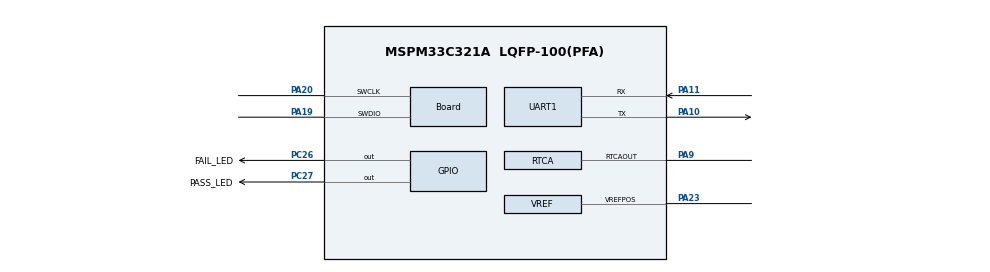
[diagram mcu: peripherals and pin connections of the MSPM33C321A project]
//@cliArgs --device "MSPM33C321A" --package "LQFP-100(PFA)" --part "Default"
//@v2CliArgs --device "MSPM33C321A" --package "LQFP-100(PFA)"
// @cliArgs --board /ti/boards/LP_MSPM33C321A --rtos nortos


/**
 * Import the modules used in this configuration.
 */
const Board  = scripting.addModule("/ti/driverlib/Board");
const GPIO   = scripting.addModule("/ti/driverlib/GPIO", {}, false);
const GPIO1  = GPIO.addInstance();
const HSADC  = scripting.addModule("/ti/driverlib/HSADC", {}, false);
const HSADC1 = HSADC.addInstance();
const RTCA   = scripting.addModule("/ti/driverlib/RTCA");
const SYSCTL = scripting.addModule("/ti/driverlib/SYSCTL");
const TIMER  = scripting.addModule("/ti/driverlib/TIMER", {}, false);
const TIMER1 = TIMER.addInstance();
const UART   = scripting.addModule("/ti/driverlib/UART", {}, false);
const UART1  = UART.addInstance();
const VREF   = scripting.addModule("/ti/driverlib/VREF");

/**
 * Write custom configuration values to the imported modules.
 */
const multiplier2         = system.clockTree["PLL_QDIV"];
multiplier2.multiplyValue = 3;

Board.InitPriority1               = "/ti/driverlib/HSADC";
Board.peripheral.$assign          = "DEBUGSS";
Board.peripheral.swclkPin.$assign = "PA20";
Board.peripheral.swdioPin.$assign = "PA19";

GPIO1.$name                               = "GPIO_LEDS";
GPIO1.associatedPins.create(2);
GPIO1.associatedPins[0].$name             = "PASS_LED";
GPIO1.associatedPins[0].launchPadShortcut = "LED2GreenEn";
GPIO1.associatedPins[0].pin.$assign       = "PC27";
GPIO1.associatedPins[1].$name             = "FAIL_LED";
GPIO1.associatedPins[1].launchPadShortcut = "LED2RedEn";
GPIO1.associatedPins[1].pin.$assign       = "PC26";

HSADC1.$name                 = "HSADC0";
HSADC1.disChan11             = true;
HSADC1.enabledSEQs           = ["ADC_SEQ_NUMBER1"];
HSADC1.adcClockPrescaler     = "DL_HSADC_CLOCK_DIVIDE_8_0";
HSADC1.enabledSOCs           = ["ADC_SOC_NUMBER0"];
HSADC1.soc0Channel           = "ADC_CH_ADCIN_11";
HSADC1.seq1Enable            = true;
HSADC1.seq1SampleWindow      = 200;
HSADC1.enabledInts           = ["ADC_INT_NUMBER_1"];
HSADC1.enableInterrupt1      = true;
HSADC1.seq1TriggerSel        = "ADC_TRIGGER_GEN_SUB_0";
HSADC1.ADCsubscriber1Channel = 1;
HSADC1.peripheral.$assign    = "ADC0";

RTCA.calSec                        = 59;
RTCA.calMin                        = 32;
RTCA.calHour                       = 10;
RTCA.calYear                       = 2026;
RTCA.enPerAlarm1                   = true;
RTCA.perAlarm1Divider              = "DIVIDE_128";
RTCA.offsetCalFreq                 = "512";
RTCA.enabledInterrupts             = ["PRESCALER1","READY"];
RTCA.peripheral.$assign            = "LFSS";
RTCA.peripheral.rtcaOutPin.$assign = "PA9";

SYSCTL.LFCLKSource = "LFXT";
SYSCTL.clockTreeEn = true;

TIMER1.$name                       = "TIMER_0";
TIMER1.interrupts                  = ["ZERO"];
TIMER1.timerMode                   = "PERIODIC";
TIMER1.timerClkDiv                 = 8;
TIMER1.event1PublisherChannel      = 1;
TIMER1.event1ControllerInterruptEn = ["ZERO_EVENT"];
TIMER1.timerPeriod                 = "300";
TIMER1.peripheral.$assign          = "TIMG12_0";

UART1.$name                    = "UART_0";
UART1.targetBaudRate           = 115200;
UART1.enableFIFO               = true;
UART1.rxFifoThreshold          = "DL_UART_RX_FIFO_LEVEL_ONE_ENTRY";
UART1.txFifoThreshold          = "DL_UART_TX_FIFO_LEVEL_EMPTY";
UART1.peripheral.$assign       = "UC12";
UART1.peripheral.rxPin.$assign = "PA11";
UART1.peripheral.txPin.$assign = "PA10";
UART1.txPinConfig.$name        = "ti_driverlib_gpio_GPIOPinGeneric1";
UART1.txPinConfig.enableConfig = true;
UART1.rxPinConfig.$name        = "ti_driverlib_gpio_GPIOPinGeneric2";

VREF.basicMode                     = "DL_VREF_ENABLE_ENABLE";
VREF.advClockConfigEnable          = true;
VREF.peripheral.$assign            = "VREF";
VREF.peripheral.vrefPosPin.$assign = "PA23";
VREF.vrefPosPinConfig.$name        = "ti_driverlib_gpio_GPIOPinGeneric0";

const ProjectConfig              = scripting.addModule("/ti/project_config/ProjectConfig", {}, false);
ProjectConfig.migrationCondition = true;
